# Z20K14xM register map
Vendor: Zhixin Semiconductor; Series: Z20K14xM; File version: 0.1.0
CPU: CM4 r0p1, little endian, no MPU, FPU, 4 interrupt priority bits
Registers are 32-bit, read-write, reset 0x0 unless marked. A register's access mark holds for its fields unless they carry their own. Offsets are from the block's base; [hi:lo] are bit positions; {n}, {i} and the like mark numbered series; 'fields as' and 'values as' point back to an identical list.

## I2S0
Base 0x40054000
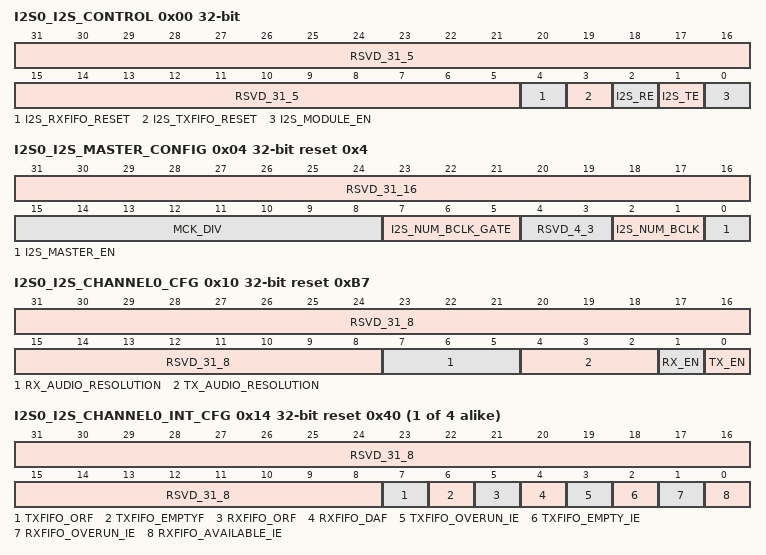
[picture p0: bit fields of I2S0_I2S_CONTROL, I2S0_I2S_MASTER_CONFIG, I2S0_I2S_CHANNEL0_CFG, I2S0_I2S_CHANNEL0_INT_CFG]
0x00 I2S0_I2S_CONTROL — I2S control register(I2S_CONTROL)
  [31:5] RSVD_31_5 — reserve
  [4] I2S_RXFIFO_RESET — I2S RXFIFO reset bit
  [3] I2S_TXFIFO_RESET — I2S TXFIFO reset bit
  [2] I2S_RE — I2S receiver enable
  [1] I2S_TE — I2S transmit enable
  [0] I2S_MODULE_EN — I2S module enable
0x04 I2S0_I2S_MASTER_CONFIG reset 0x4 — I2S master configure register(I2S_MASTER_CONFIG)
  [31:16] RSVD_31_16 — reserve
  [15:8] MCK_DIV — i2s mclk divider
  [7:5] I2S_NUM_BCLK_GATE — I2S gated after the number of bclk cycles
  [4:3] RSVD_4_3 — reserve
  [2:1] I2S_NUM_BCLK — I2S number of bclk cycles
  [0] I2S_MASTER_EN — I2S master mode enable bit
0x08 I2S0_I2S_CHANNEL0_LEFT_DATA — I2S left data0 register(I2S_LEFT_DATA0)
  [31:0] LEFT_DATA0 — channel0 left data
0x0C I2S0_I2S_CHANNEL0_RIGHT_DATA — I2S right data0 register(I2S_RIGHT_DATA0)
  [31:0] RIGHT_DATA0 — channel0 right data
0x10 I2S0_I2S_CHANNEL0_CFG reset 0xB7 — I2S channel0 configure (I2S_CHANNEL0_CFG)
  [31:8] RSVD_31_8 — reserve
  [7:5] RX_AUDIO_RESOLUTION — channeln rx audio resolution
  [4:2] TX_AUDIO_RESOLUTION — channeln tx audio resolution
  [1] RX_EN — channeln receive enable
  [0] TX_EN — channeln transmit enable
{0x14+0x14*i} I2S0_I2S_CHANNEL{i}_INT_CFG reset 0x40 (i=0..3) — I2S channel{i} interrupt register(I2S_CHANNEL{i}_INT_REG)
  [31:8] RSVD_31_8 — reserve
  [7] TXFIFO_ORF — TXFIFO overun flag
  [6] TXFIFO_EMPTYF — TXFIFO empty flag
  [5] RXFIFO_ORF — RXFIFO overun flag
  [4] RXFIFO_DAF — RXFIFO data avaliable flag
  [3] TXFIFO_OVERUN_IE — TXFIFO overun interrupt enable
  [2] TXFIFO_EMPTY_IE — TXFIFO empty interrupt enable
  [1] RXFIFO_OVERUN_IE — RXFIFO overun interrupt enable
  [0] RXFIFO_AVAILABLE_IE — RXFIFO data avaliable interrupt enable
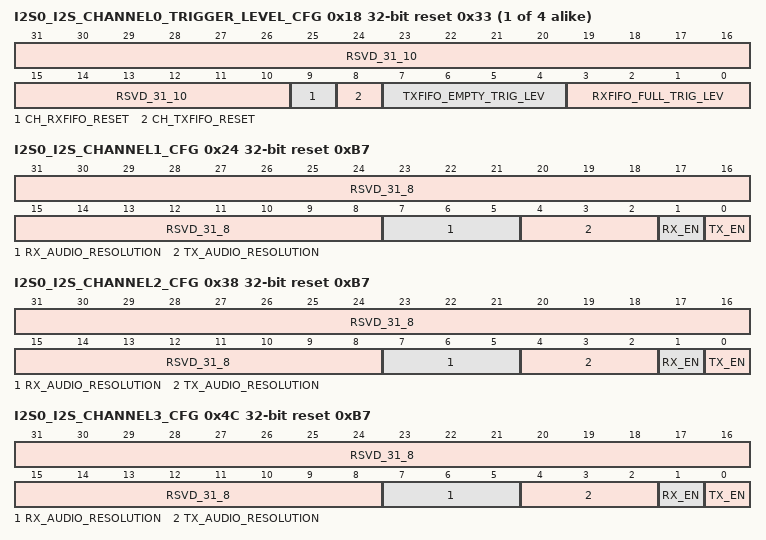
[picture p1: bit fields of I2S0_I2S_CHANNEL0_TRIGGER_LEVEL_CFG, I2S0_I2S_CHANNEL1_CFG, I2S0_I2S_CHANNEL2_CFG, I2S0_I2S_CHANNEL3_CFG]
{0x18+0x14*i} I2S0_I2S_CHANNEL{i}_TRIGGER_LEVEL_CFG reset 0x33 (i=0..3) — I2S channel{i} trigger level configure(I2S_CHANNEL{i}_TRIGGER_LEVEL_CFG)
  [31:10] RSVD_31_10 — reserve
  [9] CH_RXFIFO_RESET — channel RXFIFO channel reset
  [8] CH_TXFIFO_RESET — channel TXFIFO channel reset
  [7:4] TXFIFO_EMPTY_TRIG_LEV — channel TXFIFO empty trigger level
  [3:0] RXFIFO_FULL_TRIG_LEV — channel RXFIFO full trigger level
0x1C I2S0_I2S_CHANNEL1_LEFT_DATA — I2S left data0 register(I2S_LEFT_DATA1)
  [31:0] LEFT_DATA1 — channel1 left data
0x20 I2S0_I2S_CHANNEL1_RIGHT_DATA — I2S right data1 register(I2S_RIGHT_DATA1)
  [31:0] RIGHT_DATA1 — channel1 right data
0x24 I2S0_I2S_CHANNEL1_CFG reset 0xB7 — I2S channel1 configure (I2S_CHANNEL1_CFG)
  fields as I2S0_I2S_CHANNEL0_CFG
0x30 I2S0_I2S_CHANNEL2_LEFT_DATA — I2S left data2 register(I2S_LEFT_DATA0)
  [31:0] LEFT_DATA0 — channel2 left data
0x34 I2S0_I2S_CHANNEL2_RIGHT_DATA — I2S right data2 register(I2S_RIGHT_DATA0)
  [31:0] RIGHT_DATA0 — channel2 right data
0x38 I2S0_I2S_CHANNEL2_CFG reset 0xB7 — I2S channel2 configure (I2S_CHANNEL0_CFG)
  fields as I2S0_I2S_CHANNEL0_CFG
0x44 I2S0_I2S_CHANNEL3_LEFT_DATA — I2S left data3 register(I2S_LEFT_DATA3)
  [31:0] LEFT_DATA3 — channel3 left data
0x48 I2S0_I2S_CHANNEL3_RIGHT_DATA — I2S right data3 register(I2S_RIGHT_DATA3)
  [31:0] RIGHT_DATA3 — channel3 right data
0x4C I2S0_I2S_CHANNEL3_CFG reset 0xB7 — I2S channel3 configure (I2S_CHANNEL3_CFG)
  fields as I2S0_I2S_CHANNEL0_CFG
0x58 I2S0_I2S_CYCLE_TX_DATA — I2S cycle tx data register
  [31:0] CYCLE_TX_DATA — cycle repeatedly tx data
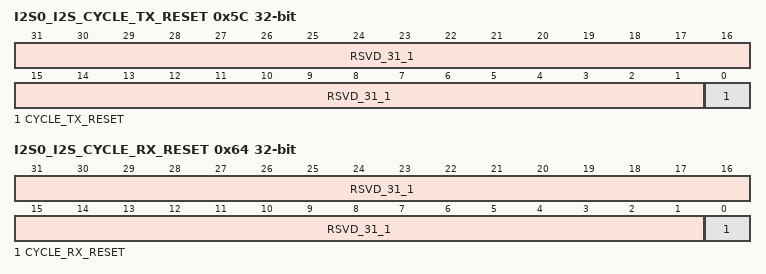
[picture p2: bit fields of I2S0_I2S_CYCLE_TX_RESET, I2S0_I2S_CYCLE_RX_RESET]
0x5C I2S0_I2S_CYCLE_TX_RESET — I2S cycle tx data reset register(I2S_CYCLE_TX_RESET)
  [31:1] RSVD_31_1 — reserve
  [0] CYCLE_TX_RESET — i2s cycle tx reset
0x60 I2S0_I2S_CYCLE_RX_DATA — I2S cycle RX data register(I2S_CYCLE_RX_DATA)
  [31:0] CYCLE_RX_DATA — cycle repeatedly rx data
0x64 I2S0_I2S_CYCLE_RX_RESET — I2S cycle rx data reset register(I2S_CYCLE_RX_RESET)
  [31:1] RSVD_31_1 — reserve
  [0] CYCLE_RX_RESET — i2s cycle rx reset

## I2S1
Base 0x40055000
Registers as I2S0 (with I2S0 read as I2S1).
